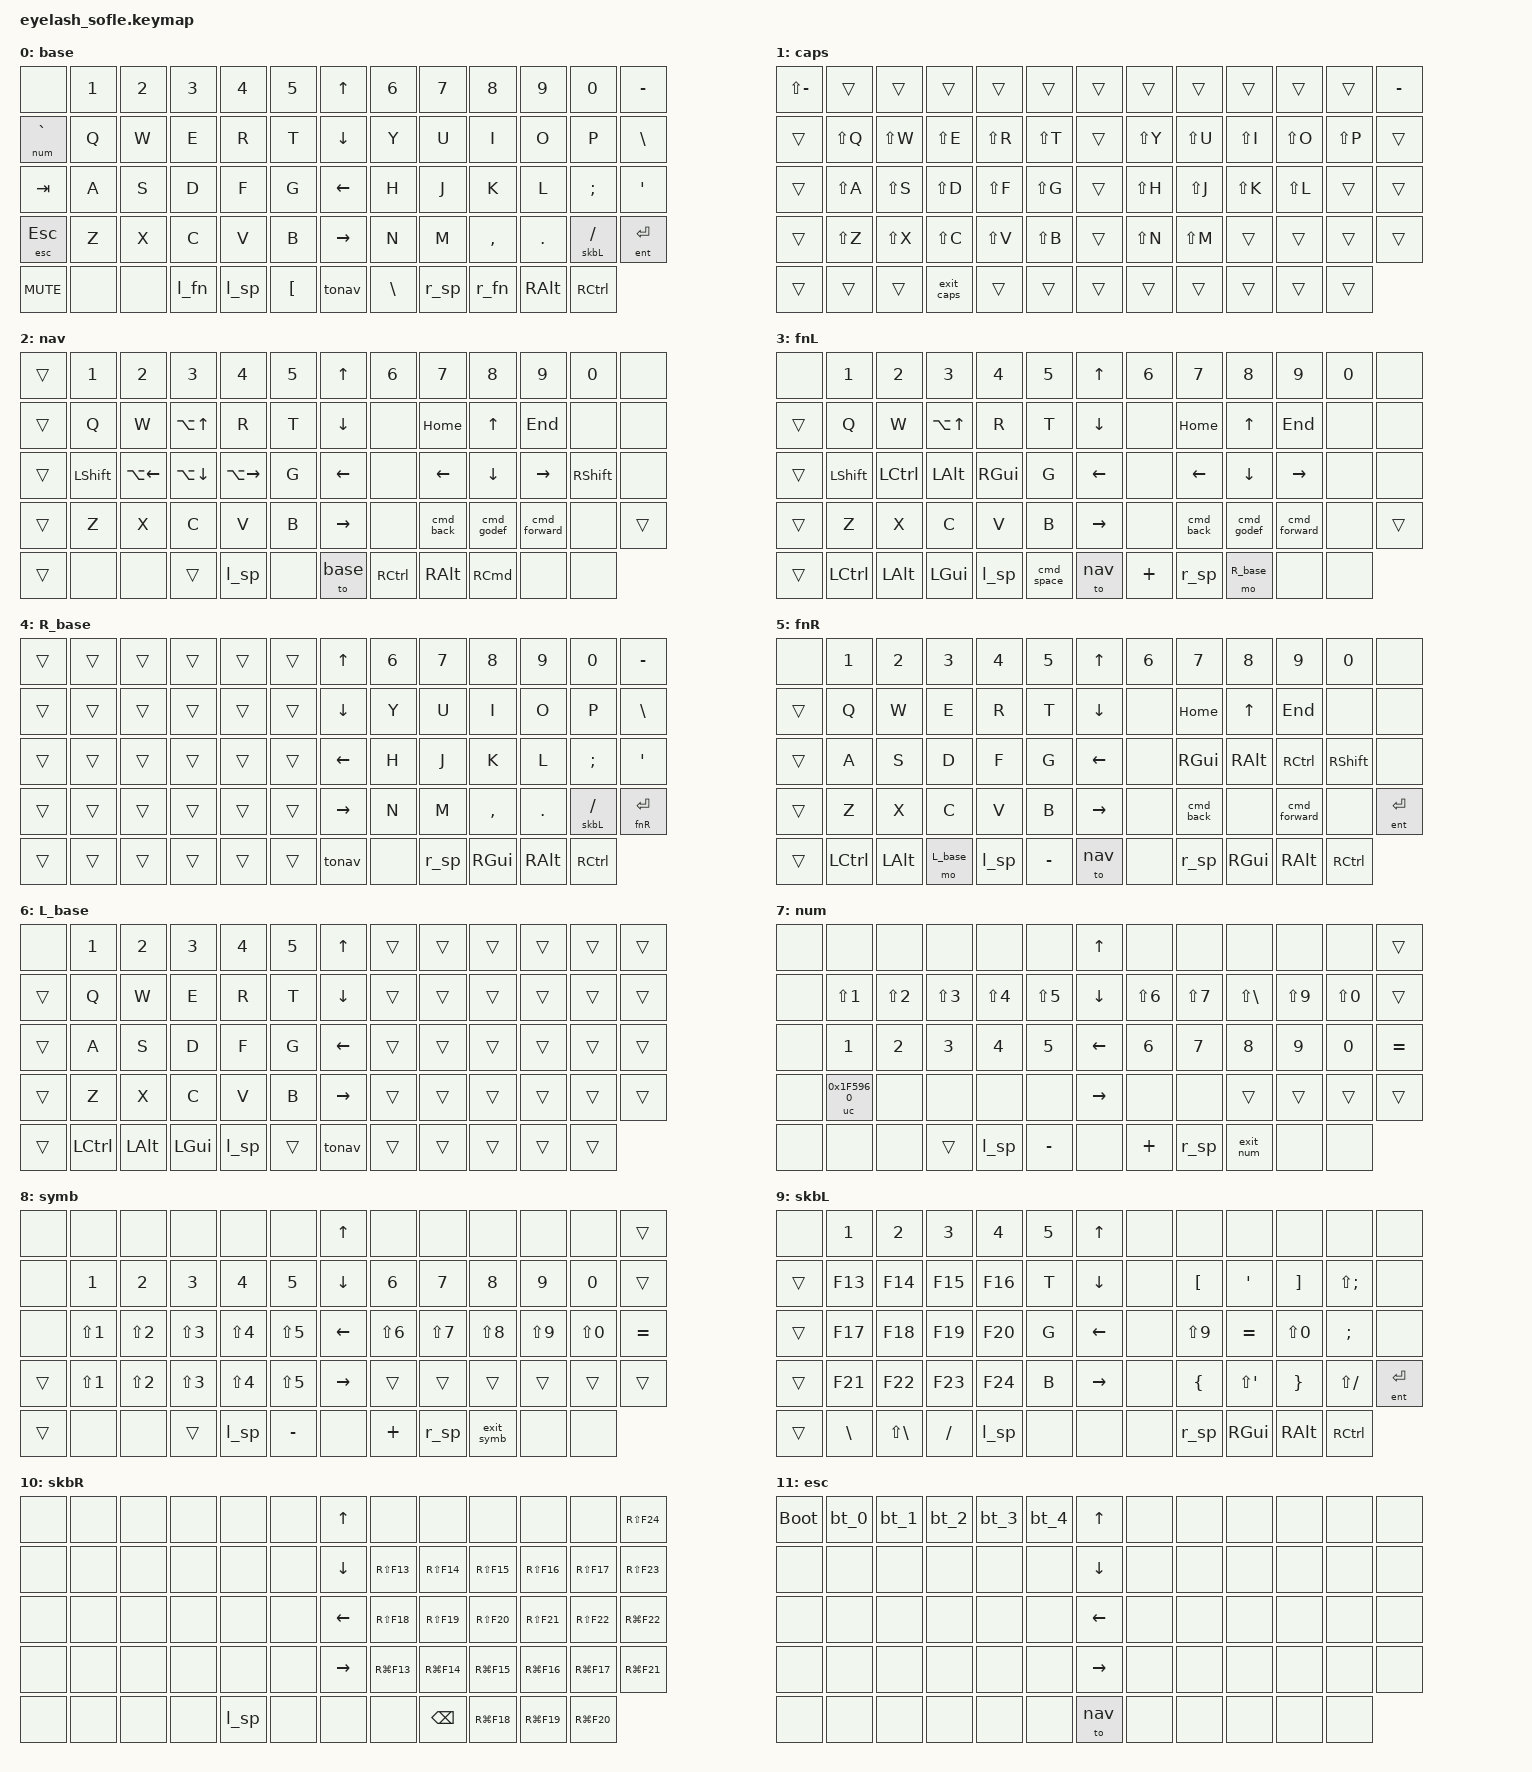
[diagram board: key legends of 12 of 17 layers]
#define ZMK_POINTING_DEFAULT_MOVE_VAL 1200  // 600
#define ZMK_POINTING_DEFAULT_SCRL_VAL 25   // 10

#include <input/processors.dtsi>
#include <zephyr/dt-bindings/input/input-event-codes.h>
#include <behaviors.dtsi>
#include <behaviors/unicode.dtsi>
#include <dt-bindings/zmk/bt.h>
#include <dt-bindings/zmk/keys.h>
#include <dt-bindings/zmk/pointing.h>
//#include <dt-bindings/zmk/ext_power.h>
//#include <dt-bindings/zmk/rgb.h>
//#include <dt-bindings/zmk/outputs.h>

#define base 0
#define caps 1 // caps_word replacement; alphas pre-shifted (kept next to base)
#define nav 2 // Navigation for programming
#define fnL 3 // Function left
#define R_base 4 // Base layer override for right hand (left side trans)
#define fnR 5 // Function right
#define L_base 6 // Base layer override for left hand (right side trans)
#define num 7 // Numpad layer
#define symb 8 // Symbols layer
#define skbL 9 // Brackets left hand
#define skbR 10 // Brackets right hand, for layer stacking
#define esc 11 // Esc layer
#define ent 12 // Enter layer
#define sp_l 13
#define sp_r 14
#define fnLn 15 // fnL variant for l_fn tap-then-hold (F-keys + numbers on right)
#define fnRn 16 // fnR variant for r_fn tap-then-hold (F-keys + numbers on left)

// Shorthand for space layer taps
#define l_sp ltr sp_l SPACE
#define r_sp ltr sp_r SPACE

// Shorthand for fn layer shift
#define l_fn fn_sh_caps fnL 0
#define r_fn fn_sh_nums fnR 0

#define bt_0 bt BT_SEL 0
#define bt_1 bt BT_SEL 1
#define bt_2 bt BT_SEL 2
#define bt_3 bt BT_SEL 3
#define bt_4 bt BT_SEL 4

// macOS F-row consumer codes — what each F-key normally does on a Mac.
// Useful when the OS-level F-key remapping isn't enabled and we want the
// "media key" behaviour directly. F5/F6 default to old-Mac keyboard
// backlight (modern Macs use Dictation/Do-Not-Disturb, which have no
// standard HID consumer codes — Karabiner is required for those).
#define _F1  C_BRI_DEC                       // Display brightness down
#define _F2  C_BRI_INC                       // Display brightness up
#define _F3  LC(UP)                          // Mission Control (Ctrl+Up shortcut)
#define _F4  C_AC_SEARCH                     // Spotlight
// _F5 (Dictation/microphone) and _F6 (Focus/Do-Not-Disturb) have no HID
// consumer codes macOS honours — they use Apple's vendor-private usage
// page. Workaround: send hyper+F5 / hyper+F6 and assign those shortcuts
// in macOS Settings → Keyboard → (Dictation / Keyboard Shortcuts →
// Mission Control → Turn Do Not Disturb On/Off).
#define _F5  LC(LA(LG(LS(F5))))              // Dictation (macOS hyper+F5 shortcut)
#define _F6  LC(LA(LG(LS(F6))))              // Focus / DND (macOS hyper+F6 shortcut)
#define _F7  C_PREV                          // Previous track
#define _F8  C_PP                            // Play / Pause
#define _F9  C_NEXT                          // Next track
#define _F10 C_MUTE                          // Mute
#define _F11 C_VOL_DN                        // Volume down
#define _F12 C_VOL_UP                        // Volume up

&uc {
  default-mode = <UC_MODE_MACOS>;  // Default to Macos input system
};

&mmv_input_listener { input-processors = <&zip_xy_scaler 2 1>; };

&msc_input_listener { input-processors = <&zip_scroll_scaler 2 1>; };

&msc {
    acceleration-exponent = <1>;      // 0
    time-to-max-speed-ms = <100>;     // 300
    delay-ms = <0>;                   // 0
};

&mmv {
    time-to-max-speed-ms = <500>;
    acceleration-exponent = <1>;
    trigger-period-ms = <16>;
};

&sk {
    release-after-ms = <1000>; // auto-release after 1000ms if no key pressed
    quick-release;             // release immediately after next key press
};

/ {
    macros {
        skp: space_with_key_press {
            compatible = "zmk,behavior-macro-one-param";
            #binding-cells = <1>;
            bindings = <&kp SPACE>, <&macro_param_1to1>, <&kp MACRO_PLACEHOLDER>;
        };

        cmd_godef: cmd_godef_macro {
            compatible = "zmk,behavior-macro";
            label = "CMD_GOTO_DEFINITION";
            #binding-cells = <0>;

            bindings = <
                &macro_press  &kp RALT
                &macro_press  &kp SEMI
            >,
            <&macro_pause_for_release>,
            <
                &macro_release &kp SEMI
                &macro_release &kp RALT
            >;
        };

        cmd_back: cmd_back_macro {
            compatible = "zmk,behavior-macro";
            label = "CMD_BACK_DEFINITION";
            #binding-cells = <0>;

            bindings = <
                &macro_press  &kp RCTRL
                &macro_press  &kp LEFT_ARROW
            >,
            <&macro_pause_for_release>,
            <
                &macro_release &kp LEFT_ARROW
                &macro_release &kp RCTRL
            >;
        };

        cmd_forward: cmd_forward_macro {
            compatible = "zmk,behavior-macro";
            label = "CMD_FORWARD_DEFINITION";
            #binding-cells = <0>;

            bindings = <
                &macro_press  &kp RCTRL
                &macro_press  &kp RIGHT_ARROW
            >,
            <&macro_pause_for_release>,
            <
                &macro_release &kp RIGHT_ARROW
                &macro_release &kp RCTRL
            >;
        };

        cmd_right: cmd_right_macro {
            compatible = "zmk,behavior-macro";
            label = "CMD_RIGHT";
            #binding-cells = <0>;

            // On key down: press and hold both Ctrl and Right
            bindings = <
                &macro_press  &kp RCTRL
                &macro_press  &kp RIGHT
            >,
            <&macro_pause_for_release>,
            <
                &macro_release &kp RIGHT
                &macro_release &kp RCTRL
            >;
        };

        cmd_left: cmd_left_macro {
            compatible = "zmk,behavior-macro";
            label = "CMD_LEFT";
            #binding-cells = <0>;

            // On key down: press and hold both Ctrl and Right
            bindings = <
                &macro_press  &kp RCTRL
                &macro_press  &kp LEFT
            >,
            <&macro_pause_for_release>,
            <
                &macro_release &kp LEFT
                &macro_release &kp RCTRL
            >;
        };
        
        cmd_end: cmd_end_macro {
            compatible = "zmk,behavior-macro";
            label = "CMD_END";
            #binding-cells = <0>;

            // On key down: press and hold both Ctrl and end
            bindings = <
                &macro_press  &kp RCTRL
                &macro_press  &kp O
            >,
            <&macro_pause_for_release>,
            <
                &macro_release &kp O
                &macro_release &kp RCTRL
            >;
        };

        cmd_home: cmd_home_macro {
            compatible = "zmk,behavior-macro";
            label = "CMD_HOME";
            #binding-cells = <0>;

            // On key down: press and hold both Ctrl and end
            bindings = <
                &macro_press  &kp RCTRL
                &macro_press  &kp U
            >,
            <&macro_pause_for_release>,
            <
                &macro_release &kp U
                &macro_release &kp RCTRL
            >;
        };

        // Used on the num layer in place of r_fn. While the `numbers`
        // auto-layer is active, this gives momentary fnR access on hold
        // (so r_fn + ; → RSHIFT, like base) and always deactivates
        // `numbers` on release. `numbers` must be deactivated *before*
        // mo fnR — the num layer has a higher index than fnR, so it
        // would otherwise shadow it.
        exit_num: exit_num {
            compatible = "zmk,behavior-macro";
            #binding-cells = <0>;
            wait-ms = <0>;
            tap-ms = <0>;
            bindings
                = <&macro_tap &numbers num>
                , <&macro_press &mo fnR>
                , <&macro_pause_for_release>
                , <&macro_release &mo fnR>
                ;
        };

        // Same as exit_num but for the symb layer.
        exit_symb: exit_symb {
            compatible = "zmk,behavior-macro";
            #binding-cells = <0>;
            wait-ms = <0>;
            tap-ms = <0>;
            bindings
                = <&macro_tap &symbols symb>
                , <&macro_press &mo fnR>
                , <&macro_pause_for_release>
                , <&macro_release &mo fnR>
                ;
        };

        // Used on the caps layer in place of l_fn. Tap exits caps mode;
        // hold gives momentary fnL access (and also exits caps on release).
        exit_caps: exit_caps {
            compatible = "zmk,behavior-macro";
            #binding-cells = <0>;
            wait-ms = <0>;
            tap-ms = <0>;
            bindings
                = <&macro_tap &capitals caps>
                , <&macro_press &mo fnL>
                , <&macro_pause_for_release>
                , <&macro_release &mo fnL>
                ;
        };

        cmd_space: cmd_space_macro {
            compatible = "zmk,behavior-macro";
            label = "CMD_SPACE";
            #binding-cells = <0>;
            wait-ms = <0>;
            tap-ms = <0>;
            bindings
                = <&macro_press &kp LGUI>
                , <&macro_tap &kp SPACE>
                , <&macro_release &kp LGUI>
                ;
        };
    };

    scroll_encoder: scroll_encoder {
        compatible = "zmk,behavior-sensor-rotate";
        #sensor-binding-cells = <0>;
        bindings = <&msc SCRL_DOWN>, <&msc SCRL_UP>;
        tap-ms = <100>;
    };

    behaviors {

        // Auto-layer used as a caps_word replacement: activates the `caps`
        // layer (where alphas are pre-shifted) and stays on while alphas,
        // numbers, or any continue-list key is pressed.
        capitals: capitals {
            compatible = "zmk,behavior-auto-layer";
            #binding-cells = <1>;
            ignore-alphas;
            ignore-numbers;
        };

        numbers: numbers {
            compatible = "zmk,behavior-auto-layer";
            #binding-cells = <1>;
            ignore-numbers;
        };

        symbols: symbols {
            compatible = "zmk,behavior-auto-layer";
            #binding-cells = <1>;
            ignore-numbers;
        };

        // Isolated hold-tap (custom, in zmk-iso-hold-tap module). Used as
        // the 2nd-tap binding of td_shift_caps to distinguish double-tap
        // (tap = `capitals` caps) from tap-then-hold (hold = mo fnLn).
        // It can safely live at the same physical position as fn_sh_caps
        // because it maintains its own active-state array.
        caps_or_fnLn: caps_or_fnLn {
            compatible = "zmk,behavior-iso-hold-tap";
            #binding-cells = <0>;
            tapping-term-ms = <200>;
            bindings = <&capitals caps>, <&mo fnLn>;
        };

        // Same pattern for r_fn: 2nd-tap of td_shift_nums distinguishes
        // double-tap (tap = `numbers` num) from tap-then-hold (hold = mo fnRn).
        nums_or_fnRn: nums_or_fnRn {
            compatible = "zmk,behavior-iso-hold-tap";
            #binding-cells = <0>;
            tapping-term-ms = <200>;
            bindings = <&numbers num>, <&mo fnRn>;
        };

        my_mt: my_mod_tap {
            compatible = "zmk,behavior-hold-tap";
            #binding-cells = <2>;
            flavor = "tap-preferred";
            tapping-term-ms = <200>;
            quick-tap-ms = <200>;
            require-prior-idle-ms = <125>;
            bindings = <&kp>, <&kp>;
        };

        tonav: tonav_behavior {
            compatible = "zmk,behavior-mod-morph";
            #binding-cells = <0>;
            bindings = <&to base>, <&to nav>;
            mods = <(MOD_LSFT|MOD_RSFT)>;
        };

        spdel: space_del {
            compatible = "zmk,behavior-mod-morph";
            #binding-cells = <0>;
            bindings = <&kp SPACE>, <&kp DEL>;
            mods = <(MOD_LSFT|MOD_RSFT)>;
        };

        spbs: space_backspace {
            compatible = "zmk,behavior-mod-morph";
            #binding-cells = <0>;
            bindings = <&kp SPACE>, <&kp BACKSPACE>;
            mods = <(MOD_LSFT|MOD_RSFT)>;
        };

        /*
        combos {
            compatible = "zmk,combos";
            combo_caps {
                timeout-ms = <150>;
                key-positions = <26 38>;
                bindings = <&kp CAPS>;
            };
        }; */

        ls_caps: double_tap_0 {
            compatible = "zmk,behavior-tap-dance";
            #binding-cells = <0>;
            tapping-term-ms = <300>;
            bindings = <&kp LSHIFT>, <&kp CAPS>;
        };

        ltr: layer_tap_retro {
            compatible = "zmk,behavior-hold-tap";
            #binding-cells = <2>;
            tapping-term-ms = <0>;
            flavor = "tap-preferred";
            require-prior-idle-ms = <200>;  // if key pressed within 500ms before, act as tap
            retro-tap;
            bindings = <&mo>, <&kp>;
        };

        // Tap-dance: 1 tap = sticky shift, 2 taps = caps word
        td_shift_caps: tap_dance_shift_caps {
            compatible = "zmk,behavior-tap-dance";
            #binding-cells = <0>;
            tapping-term-ms = <500>;
            bindings = <&sk LSHIFT>, <&caps_or_fnLn>;
        };

        // Hold-tap: hold = mo LYR, tap = tap-dance (shift / caps / fnLn).
        // quick-tap-ms forces a 2nd press within 500ms of release into the
        // tap path, so the tap-dance can see it (required for the
        // tap-then-hold → fnLn flow). Side effect: re-holding l_fn within
        // 500ms of releasing it will NOT activate mo fnL.
        fn_sh_caps: fn_layer_shift {
            compatible = "zmk,behavior-hold-tap";
            #binding-cells = <2>;
            tapping-term-ms = <200>;
            quick-tap-ms = <500>;
            flavor = "balanced";
            bindings = <&mo>, <&td_shift_caps>;
        };

        // Tap-dance: 1 tap = symbols, 2 taps = num word / fnRn (via iso-hold-tap)
        td_shift_nums: tap_dance_shift_nums {
            compatible = "zmk,behavior-tap-dance";
            #binding-cells = <0>;
            tapping-term-ms = <500>;
            bindings = <&symbols symb>, <&nums_or_fnRn>;
        };

        // Hold-tap: hold = mo LYR, tap = tap-dance (shift / num / fnRn).
        // quick-tap-ms forces a 2nd press within 500ms of release into the
        // tap path so the tap-dance can see it (required for the
        // tap-then-hold → fnRn flow). Side effect: re-holding r_fn within
        // 500ms of releasing it will NOT activate mo fnR.
        fn_sh_nums: fn_layer_shift_nums {
            compatible = "zmk,behavior-hold-tap";
            #binding-cells = <2>;
            tapping-term-ms = <200>;
            quick-tap-ms = <500>;
            flavor = "balanced";
            bindings = <&mo>, <&td_shift_nums>;
        };

    };

    keymap {
        compatible = "zmk,keymap";

//TODO: find place for left/right brackets

// Key indexes
// #00 ESC       #01 1            #02 2            #03 3              #04 4              #05 5          #06 UP             #07 6      #08 7           #09 8        #10 9      #11 0       #12 -
// #13 TAB       #14 Q            #15 W            #16 E              #17 R              #18 T          #19 DOWN           #20 Y      #21 U           #22 I        #23 O      #24 P       #25 \
// #26 `         #27 A            #28 S            #29 D              #30 F              #31 G          #32 LEFT           #33 H      #34 J           #35 K        #36 L      #37 ;       #38 '
// #39 LSH       #40 Z            #41 X            #42 C              #43 V              #44 B          #45 RIGHT          #46 N      #47 M           #48 <        #49 >      #50 /       #51 RSH
// #52 ??        #53 CTRL         #54 OPT          #55 CMD            #56 LFN            #57 SP         #58 CLICK          #59 SP     #60 RFN         #61 CMD      #62 OPT    #63 CTRL

        base {//       -           -           -           -           -           base            -           -           -           -           -           base           -           -           -           -           -           base
            bindings = <
&none            &kp N1     &kp N2    &kp N3     &kp N4    &kp N5       &kp UP_ARROW       &kp N6    &kp N7      &kp N8     &kp N9    &kp N0          &kp  MINUS
&lt num GRAVE    &kp Q      &kp W     &kp E      &kp R     &kp T        &kp DOWN_ARROW     &kp Y     &kp U       &kp I      &kp O     &kp P           &kp  BSLH
&kp TAB          &kp A      &kp S     &kp D      &kp F     &kp G        &kp LEFT_ARROW     &kp H     &kp J       &kp K      &kp L     &kp SEMI        &kp  APOS
&lt esc ESC      &kp Z      &kp X     &kp C      &kp V     &kp B        &kp RIGHT_ARROW    &kp N     &kp M       &kp COMMA  &kp DOT   &ltr skbL FSLH  &lt ent ENTER
&kp C_MUTE       &none      &none     &l_fn      &l_sp     &kp LBKT     &tonav             &kp BSLH  &r_sp       &r_fn      &kp RALT  &kp RCTRL
            >;
        };

        caps {//       -           -           -           -           -           caps            -           -           -           -           -           caps            -           -           -           -           -          caps
            bindings = <
&kp LS(MINUS)    &trans     &trans    &trans     &trans    &trans       &trans             &trans    &trans      &trans     &trans    &trans          &kp  MINUS
&trans           &kp LS(Q)  &kp LS(W) &kp LS(E)  &kp LS(R) &kp LS(T)    &trans             &kp LS(Y) &kp LS(U)   &kp LS(I)  &kp LS(O) &kp LS(P)       &trans
&trans           &kp LS(A)  &kp LS(S) &kp LS(D)  &kp LS(F) &kp LS(G)    &trans             &kp LS(H) &kp LS(J)   &kp LS(K)  &kp LS(L) &trans          &trans
&trans           &kp LS(Z)  &kp LS(X) &kp LS(C)  &kp LS(V) &kp LS(B)    &trans             &kp LS(N) &kp LS(M)   &trans     &trans    &trans          &trans
&trans           &trans     &trans    &exit_caps &trans    &trans       &trans             &trans    &trans      &trans     &trans    &trans
            >;
        };

        nav {//         -           -           -           -           -           nav            -           -           -           -           -           nav            -           -           -           -           -           nav
            bindings = <
&trans           &kp N1           &kp N2           &kp N3             &kp N4             &kp N5         &kp UP_ARROW         &kp N6     &kp N7              &kp N8              &kp N9           &kp N0              &none
&trans           &kp Q            &kp W            &kp LA(UP)         &kp R              &kp T          &kp DOWN_ARROW       &none      &kp HOME            &kp UP_ARROW        &kp END          &none               &none
&trans           &kp LSHIFT       &kp LA(LEFT)     &kp LA(DOWN)       &kp LA(RIGHT)      &kp G          &kp LEFT_ARROW       &none      &kp LEFT_ARROW      &kp DOWN_ARROW      &kp RIGHT_ARROW  &kp RSHIFT          &none
&trans           &kp Z            &kp X            &kp C              &kp V              &kp B          &kp RIGHT_ARROW      &none      &cmd_back           &cmd_godef          &cmd_forward     &none               &trans
&trans           &none            &none            &trans             &l_sp              &none          &to base             &kp RCTRL  &kp RALT            &kp RCMD            &none            &none
            >;
        };

        fnL {//         -           -           -           -           -           fnL            -           -           -           -           -           fnL            -           -           -           -           -           fnL
            bindings = <
&none            &kp N1           &kp N2           &kp N3             &kp N4             &kp N5         &kp UP_ARROW         &kp N6     &kp N7              &kp N8              &kp N9           &kp N0              &none
&trans           &kp Q            &kp W            &kp LA(UP)         &kp R              &kp T          &kp DOWN_ARROW       &none      &kp HOME            &kp UP_ARROW        &kp END          &none               &none
&trans           &kp LSHIFT       &kp LCTRL        &kp LALT           &kp RGUI           &kp G          &kp LEFT_ARROW       &none      &kp LEFT_ARROW      &kp DOWN_ARROW      &kp RIGHT_ARROW  &none               &none
&trans           &kp Z            &kp X            &kp C              &kp V              &kp B          &kp RIGHT_ARROW      &none      &cmd_back           &cmd_godef          &cmd_forward     &none               &trans
&trans           &kp LCTRL        &kp LALT         &kp LGUI           &l_sp              &cmd_space     &to nav              &kp PLUS   &r_sp               &mo R_base          &none            &none
            >;
        };

        R_base { // right side base, left side trans (should be synchronized with 'base')
            bindings = <
&trans  &trans  &trans  &trans  &trans  &trans  &kp UP_ARROW     &kp N6  &kp N7  &kp N8     &kp N9    &kp N0          &kp MINUS
&trans  &trans  &trans  &trans  &trans  &trans  &kp DOWN_ARROW   &kp Y   &kp U   &kp I      &kp O     &kp P           &kp BSLH
&trans  &trans  &trans  &trans  &trans  &trans  &kp LEFT_ARROW   &kp H   &kp J   &kp K      &kp L     &kp SEMI        &kp APOS
&trans  &trans  &trans  &trans  &trans  &trans  &kp RIGHT_ARROW  &kp N   &kp M   &kp COMMA  &kp DOT   &ltr skbL FSLH  &ltr fnR ENTER
&trans  &trans  &trans  &trans  &trans  &trans  &tonav           &none   &r_sp   &kp RGUI   &kp RALT  &kp RCTRL
            >;
        };

        fnR {//         -           -           -           -           -           fnR            -           -           -           -           -           fnR             -           -           -           -           -          fnR
            bindings = <
&none            &kp N1           &kp N2           &kp N3             &kp N4             &kp N5         &kp UP_ARROW         &kp N6     &kp N7              &kp N8              &kp N9           &kp N0              &none
&trans           &kp Q            &kp W            &kp E              &kp R              &kp T          &kp DOWN_ARROW       &none      &kp HOME            &kp UP_ARROW        &kp END          &none               &none
&trans           &kp A            &kp S            &kp D              &kp F              &kp G          &kp LEFT_ARROW       &none      &kp RGUI            &kp RALT            &kp RCTRL        &kp RSHIFT          &none
&trans           &kp Z            &kp X            &kp C              &kp V              &kp B          &kp RIGHT_ARROW      &none      &cmd_back           &none               &cmd_forward     &none               &lt ent ENTER
&trans           &kp LCTRL        &kp LALT         &mo L_base         &l_sp              &kp MINUS      &to nav              &none      &r_sp               &kp RGUI            &kp RALT         &kp RCTRL
            >;
        };

        L_base { // left side base, right side trans (should be synchronized with 'base')
            bindings = <
&none            &kp N1     &kp N2    &kp N3    &kp N4  &kp N5  &kp UP_ARROW     &trans  &trans  &trans  &trans  &trans  &trans
&trans           &kp Q      &kp W     &kp E     &kp R   &kp T   &kp DOWN_ARROW   &trans  &trans  &trans  &trans  &trans  &trans
&trans           &kp A      &kp S     &kp D     &kp F   &kp G   &kp LEFT_ARROW   &trans  &trans  &trans  &trans  &trans  &trans
&trans           &kp Z      &kp X     &kp C     &kp V   &kp B   &kp RIGHT_ARROW  &trans  &trans  &trans  &trans  &trans  &trans
&trans           &kp LCTRL  &kp LALT  &kp LGUI  &l_sp   &trans  &tonav           &trans  &trans  &trans  &trans  &trans
            >;
        };

// `~ !@#$%^&*() _+[]\{}|:"<>?
// ',./;-=

        num {//           -           -           -           -           -           num            -           -           -           -           -           num            -           -           -           -           -           num                                                                                                                                             
            bindings = <
&none            &none            &none            &none              &none              &none          &kp UP_ARROW         &none          &none               &none               &none            &none               &trans
&none            &kp LS(N1)       &kp LS(N2)       &kp LS(N3)         &kp LS(N4)         &kp LS(N5)     &kp DOWN_ARROW       &kp LS(N6)     &kp LS(N7)          &kp LS(BSLH)        &kp LS(N9)       &kp LS(N0)          &trans
&none            &kp N1           &kp N2           &kp N3             &kp N4             &kp N5         &kp LEFT_ARROW       &kp N6         &kp N7              &kp N8              &kp N9           &kp N0              &kp EQUAL
&none            &uc 0x1F596 0    &none            &none              &none              &none          &kp RIGHT_ARROW      &none          &none               &trans              &trans           &trans              &trans
&none            &none            &none            &trans             &l_sp              &kp MINUS      &none                &kp PLUS       &r_sp               &exit_num           &none            &none
            >;
        };

        symb {//           -           -           -          -           -           symb           -           -           -           -           -           symb           -           -           -           -           -           symb
            bindings = <
&none            &none            &none            &none              &none              &none          &kp UP_ARROW         &none          &none               &none               &none            &none               &trans
&none            &kp N1           &kp N2           &kp N3             &kp N4             &kp N5         &kp DOWN_ARROW       &kp N6         &kp N7              &kp N8              &kp N9           &kp N0              &trans
&none            &kp LS(N1)       &kp LS(N2)       &kp LS(N3)         &kp LS(N4)         &kp LS(N5)     &kp LEFT_ARROW       &kp LS(N6)     &kp LS(N7)          &kp LS(N8)          &kp LS(N9)       &kp LS(N0)          &kp EQUAL
&trans           &kp LS(N1)       &kp LS(N2)       &kp LS(N3)         &kp LS(N4)         &kp LS(N5)     &kp RIGHT_ARROW      &trans         &trans              &trans              &trans           &trans              &trans
&trans           &none            &none            &trans             &l_sp              &kp MINUS      &none                &kp PLUS       &r_sp               &exit_symb          &none            &none
            >;
        };

        skbL {//          -           -           -           -           -           skbL            -           -           -           -           -           skbL            -           -           -           -           -          skbL
            bindings = <
&none            &kp N1           &kp N2           &kp N3             &kp N4             &kp N5         &kp UP_ARROW         &none      &none               &none               &none            &none               &none
&trans           &kp F13          &kp F14          &kp F15            &kp F16            &kp T          &kp DOWN_ARROW       &none      &kp LBKT            &kp APOS            &kp RBKT         &kp LS(SEMI)        &none
&trans           &kp F17          &kp F18          &kp F19            &kp F20            &kp G          &kp LEFT_ARROW       &none      &kp LS(N9)          &kp EQUAL           &kp LS(N0)       &kp SEMI            &none
&trans           &kp F21          &kp F22          &kp F23            &kp F24            &kp B          &kp RIGHT_ARROW      &none      &kp LBRC            &kp LS(APOS)        &kp RBRC         &kp LS(FSLH)        &lt ent ENTER
&trans           &kp BSLH         &kp LS(BSLH)     &kp FSLH           &l_sp              &none          &none                &none      &r_sp               &kp RGUI            &kp RALT         &kp RCTRL
            >;
        };

        skbR {//          -           -           -           -           -           skbR            -           -           -           -           -           skbR            -           -           -           -           -          skbR
            bindings = <
&none  &none  &none  &none  &none  &none  &kp UP_ARROW     &none          &none          &none        &none         &none        &kp RS(F24)
&none  &none  &none  &none  &none  &none  &kp DOWN_ARROW   &kp RS(F13)    &kp RS(F14)    &kp RS(F15)  &kp RS(F16)   &kp RS(F17)  &kp RS(F23)
&none  &none  &none  &none  &none  &none  &kp LEFT_ARROW   &kp RS(F18)    &kp RS(F19)    &kp RS(F20)  &kp RS(F21)   &kp RS(F22)  &kp RG(F22)
&none  &none  &none  &none  &none  &none  &kp RIGHT_ARROW  &kp RG(F13)    &kp RG(F14)    &kp RG(F15)  &kp RG(F16)   &kp RG(F17)  &kp RG(F21)
&none  &none  &none  &none  &l_sp  &none  &none            &none          &kp BACKSPACE  &kp RG(F18)  &kp RG(F19)   &kp RG(F20)
            >;
        };

        esc {//           -           -           -           -           -           esc             -           -           -           -           -           esc             -           -           -           -           -          esc
            bindings = <
&bootloader  &bt_0  &bt_1  &bt_2  &bt_3  &bt_4  &kp UP_ARROW     &none  &none  &none  &none  &none  &none
&none        &none  &none  &none  &none  &none  &kp DOWN_ARROW   &none  &none  &none  &none  &none  &none
&none        &none  &none  &none  &none  &none  &kp LEFT_ARROW   &none  &none  &none  &none  &none  &none
&none        &none  &none  &none  &none  &none  &kp RIGHT_ARROW  &none  &none  &none  &none  &none  &none
&none        &none  &none  &none  &none  &none  &to nav          &none  &none  &none  &none  &none
            >;
        };

        ent {//           -           -           -           -           -           ent             -           -           -           -           -           ent             -           -           -           -           -          ent
            bindings = <
&none  &none  &none  &none  &none  &none  &kp UP_ARROW     &none  &none  &none  &none  &none  &bootloader
&none  &none  &none  &none  &none  &none  &kp DOWN_ARROW   &none  &none  &none  &none  &none  &none
&none  &none  &none  &none  &none  &none  &kp LEFT_ARROW   &none  &none  &none  &none  &none  &none
&none  &none  &none  &none  &none  &none  &kp RIGHT_ARROW  &none  &none  &none  &none  &none  &none
&none  &none  &none  &none  &none  &none  &to nav          &none  &none  &none  &none  &none
            >;
        };

        sp_l { // (should be synchronized with 'base')        -           -           sp_l            -           -           -           -           -           sp_l            -           -           -           -           -          sp_l
            bindings = <
&none          &skp N1  &skp N2  &skp N3  &skp N4  &skp N5   &skp UP_ARROW      &skp N6   &skp N7  &skp N8     &skp N9   &skp N0    &skp MINUS
&lt num GRAVE  &skp Q   &skp W   &skp E   &skp R   &skp T    &skp DOWN_ARROW    &skp Y    &skp U   &skp I      &skp O    &skp P     &skp BSLH
&skp TAB       &skp A   &skp S   &skp D   &skp F   &skp G    &skp LEFT_ARROW    &skp H    &skp J   &skp K      &skp L    &skp SEMI  &skp APOS
&skp ESC       &skp Z   &skp X   &skp C   &skp V   &skp B    &skp RIGHT_ARROW   &skp N    &skp M   &skp COMMA  &skp DOT  &skp FSLH  &skp ENTER
&kp C_MUTE     &none    &none    &none    &none    &none     &to nav            &skp R    &kp BSPC &none       &none     &none
            >;
        };

        sp_r { // (should be synchronized with 'base')        -           -           sp_r            -           -           -           -           -           sp_r            -           -           -           -           -          sp_r
            bindings = <
&none            &skp N1     &skp N2    &skp N3    &skp N4   &skp N5   &skp UP_ARROW     &skp N6  &skp N7        &skp N8     &skp N9    &skp N0         &skp MINUS
&lt num GRAVE    &skp Q      &skp W     &skp E     &skp R    &skp T    &skp DOWN_ARROW   &skp Y   &skp U         &skp I      &skp O     &skp P          &skp BSLH
&skp TAB         &skp A      &skp S     &skp D     &skp F    &skp G    &skp LEFT_ARROW   &skp H   &skp J         &skp K      &skp L     &skp SEMI       &skp APOS
&skp ESC         &skp Z      &skp X     &skp C     &skp V    &skp B    &skp RIGHT_ARROW  &skp N   &skp M         &skp COMMA  &skp DOT   &skp FSLH       &skp ENTER
&kp C_MUTE       &none       &none      &none      &kp DEL   &none     &to nav           &none    &none          &none       &none      &none
            >;
        };

        // fnL variant: same left-hand modifiers (shift/ctrl/alt/gui on asdf)
        // but right hand has F-keys on yuiop\ and digits on hjkl;.
        // Activated by tap-then-hold of l_fn (see caps_or_fnLn).
        fnLn {//           -           -           -           -           -           fnLn            -           -           -           -           -           fnLn           -           -           -           -           -          fnLn
            bindings = <
&trans  &trans      &trans      &trans      &trans      &trans      &trans  &trans    &trans   &trans   &trans   &trans    &kp F12
&trans  &trans      &trans      &trans      &trans      &trans      &trans  &kp F6    &kp F7   &kp F8   &kp F9   &kp F10   &kp F11
&trans  &kp LSHIFT  &kp LCTRL   &kp LALT    &kp RGUI    &trans      &trans  &kp N6    &kp N7   &kp N8   &kp N9   &kp N0    &kp _F12
&trans  &trans      &trans      &trans      &trans      &trans      &trans  &kp _F6   &kp _F7  &kp _F8  &kp _F9  &kp _F10  &kp _F11
&trans  &trans      &trans      &trans      &trans      &trans      &trans  &kp PLUS  &trans   &trans   &trans   &trans
            >;
        };

        // Mirror of fnLn for r_fn: keeps fnR's right-hand modifiers
        // (gui/alt/ctrl/shift on jkl;) and adds F-keys on qwert and digits
        // on asdfg. Activated by tap-then-hold of r_fn (see nums_or_fnRn).
        fnRn {//           -           -           -           -           -           fnRn             -           -           -           -           -          fnRn           -           -           -           -           -          fnRn
            bindings = <
&trans   &trans    &trans   &trans   &trans   &trans     &trans   &trans   &trans      &trans      &trans      &trans      &trans
&trans   &kp F1    &kp F2   &kp F3   &kp F4   &kp F5     &trans   &trans   &trans      &trans      &trans      &trans      &trans
&trans   &kp N1    &kp N2   &kp N3   &kp N4   &kp N5     &trans   &trans   &kp RGUI    &kp RALT    &kp RCTRL   &kp RSHIFT  &trans
&trans   &kp _F1   &kp _F2  &kp _F3  &kp _F4  &kp _F5    &trans   &trans   &trans      &trans      &trans      &trans      &trans
&trans   &trans    &trans   &trans   &trans   &kp MINUS  &trans   &trans   &trans      &trans      &trans      &trans
            >;
        };
    };
};

&numbers {
    continue-list = <BACKSPACE DELETE DOT COMMA MINUS PLUS EQUAL UNDERSCORE SLASH>;
};

&symbols {
    continue-list = <BACKSPACE DELETE>;
};

&capitals {
    continue-list = <BACKSPACE DELETE UNDERSCORE MINUS>;
};


// Old layers just for reference
//
//         // disabling my_mt keys
//         layer0 {
//             bindings = <
// &kp ESC          &kp N1           &kp N2           &kp N3             &kp N4             &kp N5         &kp UP_ARROW         &kp N6     &kp N7              &kp N8              &kp N9           &kp N0              &kp MINUS
// &kp TAB          &kp Q            &kp W            &kp E              &kp R              &kp T          &kp DOWN_ARROW       &kp Y      &kp U               &kp I               &kp O            &kp P               &kp BSLH
// &kp TILDE        &kp A            &my_mt LCTRL S   &my_mt LEFT_ALT D  &my_mt LEFT_GUI F  &kp G          &kp LEFT_ARROW       &kp H      &my_mt RIGHT_GUI J  &my_mt RIGHT_ALT K  &my_mt RCTRL L   &kp SEMI            &kp APOS
// &tt0             &kp Z            &kp X            &kp C              &kp V              &kp B          &kp RIGHT_ARROW      &kp N      &kp M               &kp COMMA           &kp DOT          &kp FSLH            &kp RSHIFT
// &kp C_MUTE       &kp LCTRL        &kp LALT         &kp LGUI           &mo 1              &spdel         &kp ENTER            &spbs      &lt 2 ENTER         &kp RGUI            &kp RALT         &kp RCTRL
//             >;
//         };
//
//         layer_1 { // layer 1 (not used in this config)
//             bindings = <
// &kp GRAVE   &kp F1           &kp F2          &kp F3           &kp F4           &kp F5             &mmv MOVE_UP     &kp F6           &kp F7           &kp F8      &kp F9     &kp F10           &trans
// &trans      &kp GRAVE        &mkp LCLK       &mkp MCLK        &mkp RCLK        &mkp MB4           &mmv MOVE_DOWN   &kp PG_UP        &kp HOME         &kp UP      &kp END    &kp MINUS         &kp EQUAL
// &trans      &kp TILDE        &trans          &trans           &trans           &mkp MB5           &mmv MOVE_LEFT   &kp PG_DN        &kp LEFT         &kp DOWN    &kp RIGHT  &cmd_godef        &kp RIGHT_BRACKET
// &trans      &rgb_ug RGB_OFF  &rgb_ug RGB_ON  &rgb_ug RGB_EFF  &rgb_ug RGB_EFR  &rgb_ug RGB_SPI    &mmv MOVE_RIGHT  &rgb_ug RGB_BRI  &rgb_ug RGB_BRD  &kp INSERT  &kp F11    &kp F12           &trans
// &kp C_MUTE  &trans           &trans          &trans           &trans           &trans             &none            &trans           &trans           &trans      &trans     &trans
//             >;
//         };
// 
//         layer_2 { // layer 2 (not used in this config)
//             bindings = <
// &kp TILDE  &bt BT_SEL 0  &bt BT_SEL 1    &bt BT_SEL 2  &bt BT_SEL 3  &bt BT_SEL 4    &mmv MOVE_UP     &bt BT_CLR  &bt BT_CLR_ALL  &out OUT_USB  &out OUT_BLE  &sys_reset   &trans
// &trans     &none         &none           &trans        &trans        &trans          &mmv MOVE_DOWN   &trans      &trans          &kp F11       &kp F12       &kp UNDER    &kp PLUS
// &trans     &none         &none           &trans        &trans        &trans          &mmv MOVE_LEFT   &trans      &trans          &trans        &trans        &kp LBRC     &kp RBRC
// &trans     &none         &trans          &bootloader   &trans        &trans          &mmv MOVE_RIGHT  &trans      &trans          &sys_reset    &soft_off     &bootloader  &trans
// &trans     &trans        &trans          &trans        &trans        &trans          &none            &trans      &trans          &trans        &trans        &trans
//             >;
//         };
